AUTOSAR XML (schema 314)
package /ComponentType
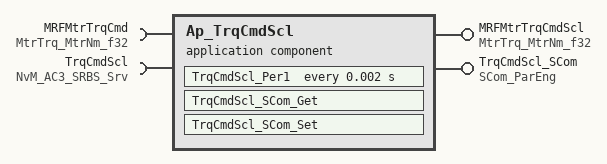
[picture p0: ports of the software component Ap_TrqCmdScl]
  application software component type Ap_TrqCmdScl
    provide port MRFMtrTrqCmdScl: unqueued-sender-com-spec{data-element=MtrNm_f32, can-invalidate=false, init-value=D_ZERO_ULS_F32}, provided-interface=MtrTrq_MtrNm_f32
    provide port TrqCmdScl_SCom: provided-com-specs=[{operation=Get, queue-length=1}, {operation=Set, queue-length=1}], provided-interface=SCom_ParEng
    require port MRFMtrTrqCmd: unqueued-receiver-com-spec{data-element=MtrNm_f32, init-value=D_ZERO_ULS_F32}, required-interface=MtrTrq_MtrNm_f32
    require port TrqCmdScl: required-com-specs=[EraseBlock, GetErrorStatus, InvalidateNvBlock, ReadBlock, SetRamBlockStatus, WriteBlock], required-interface=NvM_AC3_SRBS_Srv
  internal behavior Ap_TrqCmdScl_InternalBehavior: component=Ap_TrqCmdScl
    timing event TMT_TrqCmdScl_Per1: start-on-event=TrqCmdScl_Per1, period=0.002
    operation invoked event OIT_TrqCmdScl_SCom_Get_TrqCmdScl_SCom_Get: start-on-event=TrqCmdScl_SCom_Get, operation=TrqCmdScl_SCom.Get
    operation invoked event OIT_TrqCmdScl_SCom_Set_TrqCmdScl_SCom_Set: start-on-event=TrqCmdScl_SCom_Set, operation=TrqCmdScl_SCom.Set
    per instance memory TorqueCmdSF_Uls_f32: type=Float, type-definition=/DataType/Float
    port-api-options:
      enable-take-address=false, indirect-api=false, port=MRFMtrTrqCmd
      enable-take-address=false, indirect-api=false, port=MRFMtrTrqCmdScl
      enable-take-address=false, indirect-api=false, port=TrqCmdScl
      enable-take-address=false, indirect-api=false, port=TrqCmdScl_SCom
    runnable TrqCmdScl_Per1
      data read access READ_MRFMtrTrqCmd_MtrNm_f32: data-element=MRFMtrTrqCmd.MtrNm_f32
      data write access WRITE_MRFMtrTrqCmdScl_MtrNm_f32: data-element=MRFMtrTrqCmdScl.MtrNm_f32
    runnable TrqCmdScl_SCom_Get
    runnable TrqCmdScl_SCom_Set
      sync call SC_TrqCmdScl_WriteBlock: operation=TrqCmdScl.WriteBlock, timeout=0
    service-needss:
      swc nv block needs TorqueCmdSF_EOLData: n-data-sets=0, readonly=false, reliability=LOW, resistant-to-changed-sw=false, restore-at-start=false, write-only-once=false, writing-frequency=0, writing-priority=LOW, mirror-block=TorqueCmdSF_Uls_f32
  swc implementation Ap_TrqCmdScl_Implementation: behavior=Ap_TrqCmdScl_InternalBehavior
    code-descriptors:
      code Code: type=SRC
